# VPAC0_PAR_VPAC_VISS0_S_VBUSP_VISS_RAWFE_CFG_MMR_S_VBUSP_RAWFE_CFG register map
Vendor: Texas Instruments
Peripheral module from a debugger description file (folder J7ES).
Registers are 32-bit, access per field, reset values left out (the file's numbers can be read two ways) unless marked. A register's access mark holds for its fields unless they carry their own. Offsets are as the file gives them; lines under a group give offsets from that group; [hi:lo] are bit positions; {n}, {i} and the like mark numbered series; 'fields as' and 'values as' point back to an identical list; <NAME> marks a mode.

## VPAC0_PAR_VPAC_VISS0_S_VBUSP_VISS_RAWFE_CFG_MMR_S_VBUSP_RAWFE_CFG
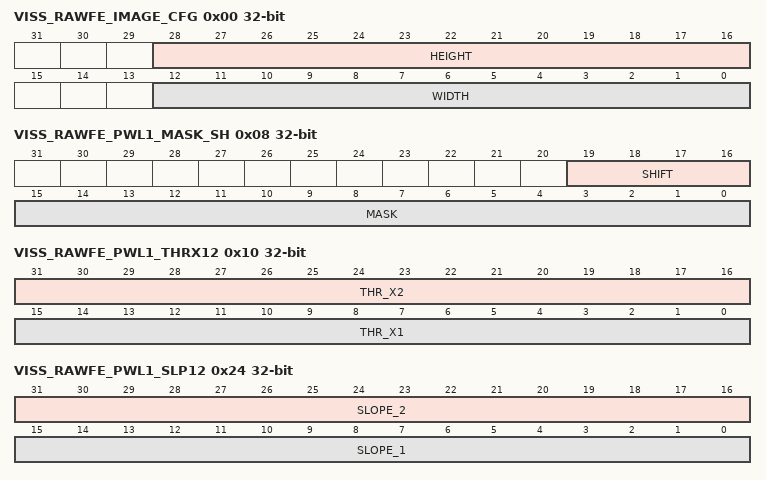
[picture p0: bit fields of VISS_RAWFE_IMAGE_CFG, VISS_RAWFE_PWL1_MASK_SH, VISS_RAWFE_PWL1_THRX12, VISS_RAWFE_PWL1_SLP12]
0x00 VISS_RAWFE_IMAGE_CFG — Input image width and height.
  [28:16] HEIGHT rw — image height
  [12:0] WIDTH rw — image width
0x04 VISS_RAWFE_SHADOW_CFG rw — shadow configuration
  [0] LUT3_SHDW_EN — use LUT2 ram as LUT table for LUT3 processing
0x08 VISS_RAWFE_PWL1_MASK_SH — Long frame PWL mask and shift values
  [19:16] SHIFT rw — number of right shift
  [15:0] MASK rw — mask bit pattern
0x0C VISS_RAWFE_PWL1_EN — Long frame PWL enable
  [0] ENABLE rw
0x10 VISS_RAWFE_PWL1_THRX12 rw — Long frame PWL threshold X1 and X2 - Unsigned
  [31:16] THR_X2 — threshold X2
  [15:0] THR_X1 — threshold X1
0x14 VISS_RAWFE_PWL1_THRX3 — Long frame PWL threshold X3 - Unsigned
  [15:0] THR_X3 rw — threshold X3
{0x14+4i} VISS_RAWFE_PWL1_THRY{i} (i=1..3) — Long frame PWL threshold Y{i} - Unsigned
  [23:0] THR_Y{i} rw — threshold Y{i}
0x24 VISS_RAWFE_PWL1_SLP12 rw — Long frame PWL slope 1 and 2 - Unsigned
  [31:16] SLOPE_2, [15:0] SLOPE_1
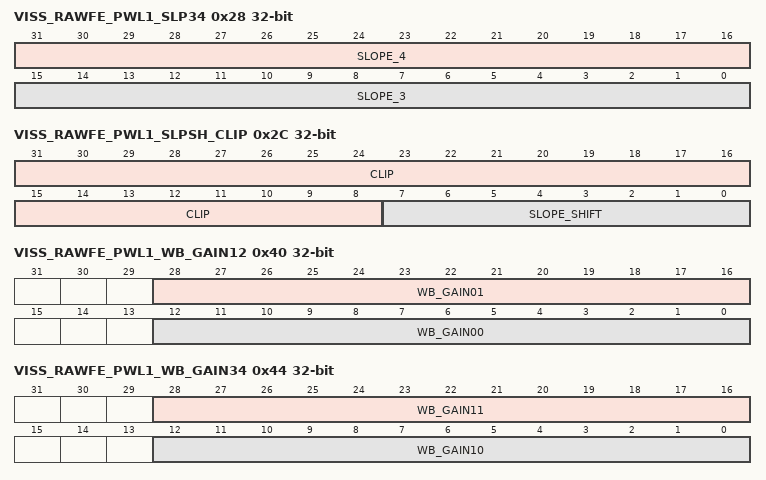
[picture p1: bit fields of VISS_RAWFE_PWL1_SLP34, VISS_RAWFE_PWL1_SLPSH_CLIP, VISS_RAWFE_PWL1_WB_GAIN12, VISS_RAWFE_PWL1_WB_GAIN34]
0x28 VISS_RAWFE_PWL1_SLP34 rw — Long frame PWL slope 3 and 4 - Unsigned
  [31:16] SLOPE_4, [15:0] SLOPE_3
0x2C VISS_RAWFE_PWL1_SLPSH_CLIP rw — Long frame PWL slope shift and clip
  [31:8] CLIP — clip value
  [7:0] SLOPE_SHIFT — shift value for slope, must not exceed decimal 33.
0x30 VISS_RAWFE_PWL1_OFF1 — Long frame Offset 1
  [23:0] OFST00 rw — S24, Offset at pixel 00
0x34 VISS_RAWFE_PWL1_OFF2 — Long frame Offset 2
  [23:0] OFST01 rw — S24, Offset at pixel 01
0x38 VISS_RAWFE_PWL1_OFF3 — Long frame Offset 3
  [23:0] OFST10 rw — S24, Offset at pixel 10
0x3C VISS_RAWFE_PWL1_OFF4 — Long frame Offset 4
  [23:0] OFST11 rw — S24, Offset at pixel 11
0x40 VISS_RAWFE_PWL1_WB_GAIN12 — Long Frame white balance gain 1 and 2
  [28:16] WB_GAIN01 rw — U13Q9, WB gain at pixel 01
  [12:0] WB_GAIN00 rw — U13Q9, WB gain at pixel 00
0x44 VISS_RAWFE_PWL1_WB_GAIN34 — Long Frame white balance gain 3 and 4
  [28:16] WB_GAIN11 rw — U13Q9, WB gain at pixel 11
  [12:0] WB_GAIN10 rw — U13Q9, WB gain at pixel 10
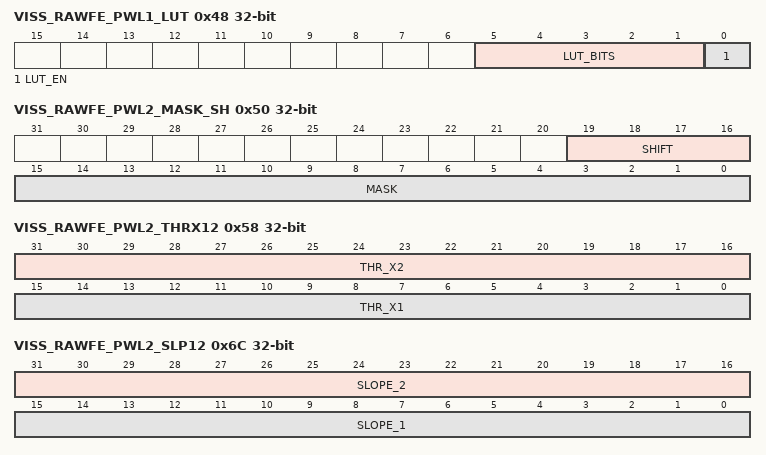
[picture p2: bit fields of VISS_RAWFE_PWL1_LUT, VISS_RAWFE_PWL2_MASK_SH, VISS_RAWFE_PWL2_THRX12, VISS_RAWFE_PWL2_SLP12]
0x48 VISS_RAWFE_PWL1_LUT — Long frame PWL LUT configuration
  [5:1] LUT_BITS rw — LUT input bit depth, up to 24
  [0] LUT_EN rw — enable LUT based compression
0x4C VISS_RAWFE_PWL1_LUTCLIP — Long frame PWL LUT output clip value
  [15:0] LUTCLIP rw — LUT clip value
0x50 VISS_RAWFE_PWL2_MASK_SH — Short frame PWL mask and shift values
  fields as VISS_RAWFE_PWL1_MASK_SH
0x54 VISS_RAWFE_PWL2_EN — Short frame PWL enable
  [0] ENABLE rw
0x58 VISS_RAWFE_PWL2_THRX12 rw — Short frame PWL threshold X1 and X2 - Unsigned
  [31:16] THR_X2 — threshold X2
  [15:0] THR_X1 — threshold X1
0x5C VISS_RAWFE_PWL2_THRX3 — Short frame PWL threshold X3 - Unsigned
  [15:0] THR_X3 rw — threshold X3
{0x5C+4i} VISS_RAWFE_PWL2_THRY{i} (i=1..3) — Short frame PWL threshold Y{i} - Unsigned
  [23:0] THR_Y{i} rw — threshold Y{i}
0x6C VISS_RAWFE_PWL2_SLP12 rw — Short frame PWL slope 1 and 2 - Unsigned
  [31:16] SLOPE_2, [15:0] SLOPE_1
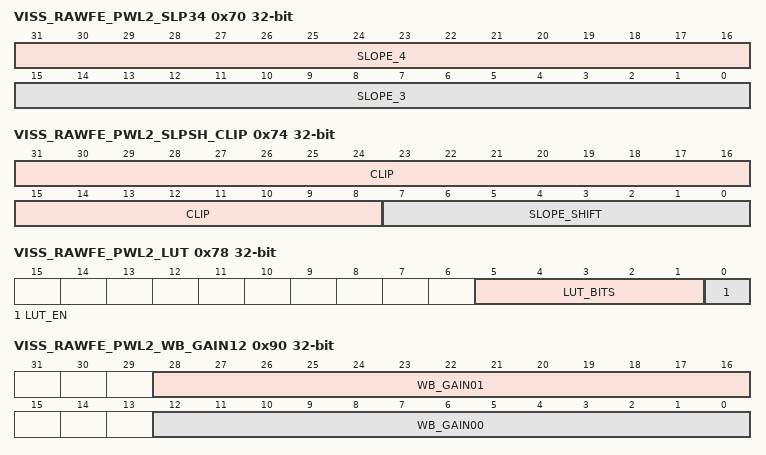
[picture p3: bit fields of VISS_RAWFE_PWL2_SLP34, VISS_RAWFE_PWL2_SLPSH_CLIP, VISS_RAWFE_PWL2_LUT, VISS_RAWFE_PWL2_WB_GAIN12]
0x70 VISS_RAWFE_PWL2_SLP34 rw — Short frame PWL slope 3 and 4 - Unsigned
  [31:16] SLOPE_4, [15:0] SLOPE_3
0x74 VISS_RAWFE_PWL2_SLPSH_CLIP rw — Short frame PWL slope shift and clip
  [31:8] CLIP — clip value
  [7:0] SLOPE_SHIFT — shift value for slope, must not exceed decimal 33
0x78 VISS_RAWFE_PWL2_LUT — Short frame PWL LUT configuration
  fields as VISS_RAWFE_PWL1_LUT
0x7C VISS_RAWFE_PWL2_LUTCLIP — Short frame PWL LUT output clip value
  [15:0] LUTCLIP rw — LUT clip value
0x80 VISS_RAWFE_PWL2_OFF1 — Short frame WB Offset 1
  [23:0] OFST00 rw — S24, WB Offset at pixel 00
0x84 VISS_RAWFE_PWL2_OFF2 — Short frame Offset 2
  [23:0] OFST01 rw — S24, Offset at pixel 01
0x88 VISS_RAWFE_PWL2_OFF3 — Short frame Offset 3
  [23:0] OFST10 rw — S24, Offset at pixel 10
0x8C VISS_RAWFE_PWL2_OFF4 — Short frame Offset 4
  [23:0] OFST11 rw — S24, Offset at pixel 11
0x90 VISS_RAWFE_PWL2_WB_GAIN12 — Short Frame white balance gain 1 and 2
  fields as VISS_RAWFE_PWL1_WB_GAIN12
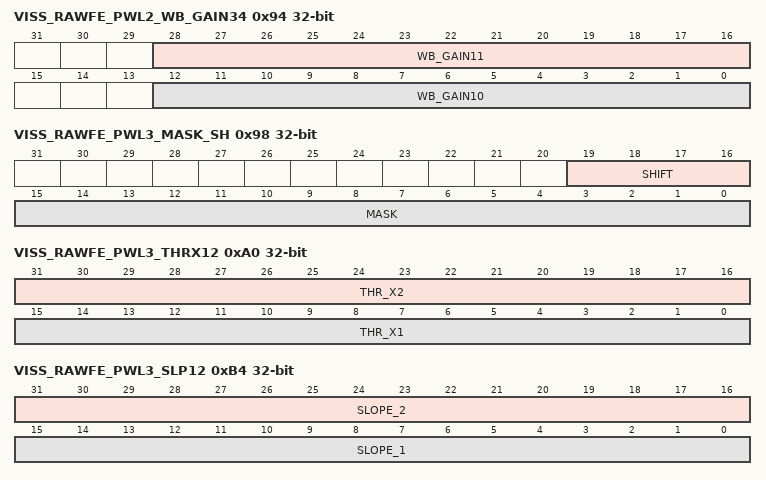
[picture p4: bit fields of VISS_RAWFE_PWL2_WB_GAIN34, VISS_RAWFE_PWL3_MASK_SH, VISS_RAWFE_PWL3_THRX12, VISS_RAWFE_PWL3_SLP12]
0x94 VISS_RAWFE_PWL2_WB_GAIN34 — Short Frame white balance gain 3 and 4
  fields as VISS_RAWFE_PWL1_WB_GAIN34
0x98 VISS_RAWFE_PWL3_MASK_SH — Very short frame PWL mask and shift values
  fields as VISS_RAWFE_PWL1_MASK_SH
0x9C VISS_RAWFE_PWL3_EN — Very short frame PWL enable
  [0] ENABLE rw
0xA0 VISS_RAWFE_PWL3_THRX12 rw — Very short frame PWL threshold X1 and X2 - Unsigned
  [31:16] THR_X2 — threshold X2
  [15:0] THR_X1 — threshold X1
0xA4 VISS_RAWFE_PWL3_THRX3 — Very short frame PWL threshold X3 - Unsigned
  [15:0] THR_X3 rw — threshold X3
{0xA4+4i} VISS_RAWFE_PWL3_THRY{i} (i=1..3) — Very short frame PWL threshold Y{i} - Unsigned
  [23:0] THR_Y{i} rw — threshold Y{i}
0xB4 VISS_RAWFE_PWL3_SLP12 rw — Very short frame PWL slope 1 and 2 - Unsigned
  [31:16] SLOPE_2, [15:0] SLOPE_1
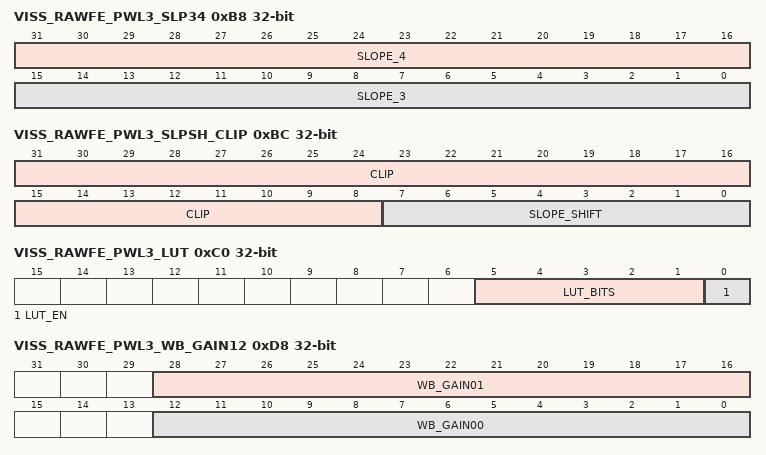
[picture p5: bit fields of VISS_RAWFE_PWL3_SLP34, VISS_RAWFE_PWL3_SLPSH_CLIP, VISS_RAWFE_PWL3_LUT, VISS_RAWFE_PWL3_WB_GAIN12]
0xB8 VISS_RAWFE_PWL3_SLP34 rw — Very short frame PWL slope 3 and 4 - Unsigned
  [31:16] SLOPE_4, [15:0] SLOPE_3
0xBC VISS_RAWFE_PWL3_SLPSH_CLIP rw — Very short frame PWL slope shift and clip
  fields as VISS_RAWFE_PWL2_SLPSH_CLIP
0xC0 VISS_RAWFE_PWL3_LUT — Very short frame PWL LUT configuration
  fields as VISS_RAWFE_PWL1_LUT
0xC4 VISS_RAWFE_PWL3_LUTCLIP — Very short frame PWL LUT output clip value
  [15:0] LUTCLIP rw — LUT clip value
0xC8 VISS_RAWFE_PWL3_OFF1 — Very Short frame Offset 1
  [23:0] OFST00 rw — S24, Offset at pixel 00
0xCC VISS_RAWFE_PWL3_OFF2 — Very Short frame Offset 2
  [23:0] OFST01 rw — S24, Offset at pixel 01
0xD0 VISS_RAWFE_PWL3_OFF3 — Very Short frame Offset 3
  [23:0] OFST10 rw — S24, Offset at pixel 10
0xD4 VISS_RAWFE_PWL3_OFF4 — Very Short frame Offset 4
  [23:0] OFST11 rw — S24, Offset at pixel 11
0xD8 VISS_RAWFE_PWL3_WB_GAIN12 — Very Short Frame white balance gain 1 and 2
  fields as VISS_RAWFE_PWL1_WB_GAIN12
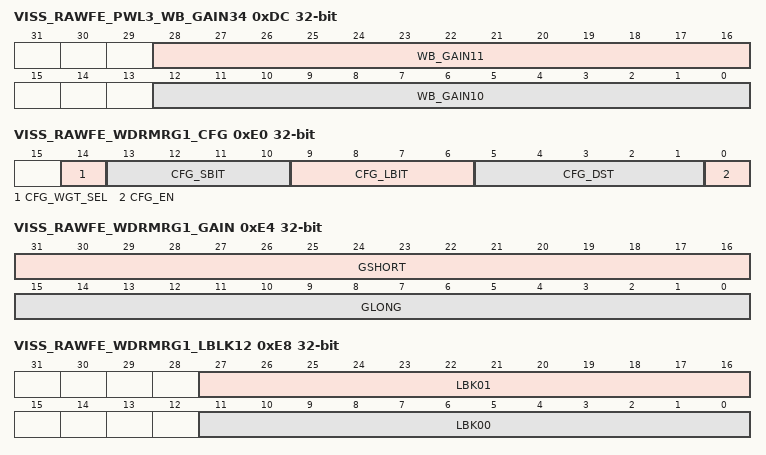
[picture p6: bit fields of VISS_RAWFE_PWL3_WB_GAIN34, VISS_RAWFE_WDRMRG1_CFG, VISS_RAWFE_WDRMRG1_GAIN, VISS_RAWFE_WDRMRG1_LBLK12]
0xDC VISS_RAWFE_PWL3_WB_GAIN34 — Very Short Frame white balance gain 3 and 4
  fields as VISS_RAWFE_PWL1_WB_GAIN34
0xE0 VISS_RAWFE_WDRMRG1_CFG — First stage WDR merge configuration
  [14] CFG_WGT_SEL rw — Select source for weight calculation (
  [13:10] CFG_SBIT rw — U4, short exposure image bit shift
  [9:6] CFG_LBIT rw — U4, long exposure image bit shift
  [5:1] CFG_DST rw — U5, down shift value after WDR merge
  [0] CFG_EN rw — enable
0xE4 VISS_RAWFE_WDRMRG1_GAIN rw — First stage WDR merge gain
  [31:16] GSHORT — U16Q15, gain for long frame
  [15:0] GLONG — U16Q15, gain for short frame
0xE8 VISS_RAWFE_WDRMRG1_LBLK12 — First stage WDR merge black level 1 and 2 for long frame
  [27:16] LBK01 rw — U12, black level for long frame at pixel 01
  [11:0] LBK00 rw — U12, black level for long frame at pixel 00
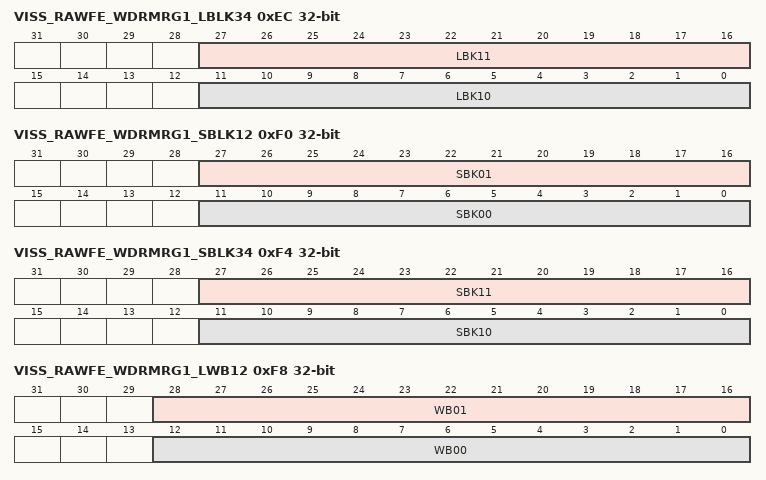
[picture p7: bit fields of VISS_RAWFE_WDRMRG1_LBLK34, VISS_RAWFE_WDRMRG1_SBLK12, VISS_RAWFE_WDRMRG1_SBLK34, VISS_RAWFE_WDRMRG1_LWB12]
0xEC VISS_RAWFE_WDRMRG1_LBLK34 — First stage WDR merge black level 3 and 4 for long frame
  [27:16] LBK11 rw — U12, black level for long frame at pixel 11
  [11:0] LBK10 rw — U12, black level for long frame at pixel 10
0xF0 VISS_RAWFE_WDRMRG1_SBLK12 — First stage WDR merge black level 1 and 2 for short frame
  [27:16] SBK01 rw — U12, black level for short frame at pixel 01
  [11:0] SBK00 rw — U12, black level for short frame at pixel 00
0xF4 VISS_RAWFE_WDRMRG1_SBLK34 — First stage WDR merge black level 3 and 4 for short frame
  [27:16] SBK11 rw — U12, black level for short frame at pixel 11
  [11:0] SBK10 rw — U12, black level for short frame at pixel 10
0xF8 VISS_RAWFE_WDRMRG1_LWB12 — First stage WDR merge WB gain 1 and 2 for long frame
  [28:16] WB01 rw — U13Q9, WB gain for long frame at pixel 01
  [12:0] WB00 rw — U13Q9, WB gain for long frame at pixel 00
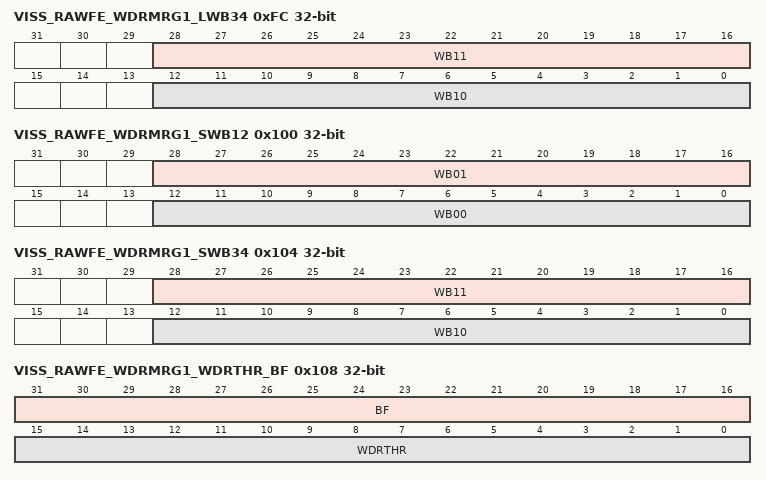
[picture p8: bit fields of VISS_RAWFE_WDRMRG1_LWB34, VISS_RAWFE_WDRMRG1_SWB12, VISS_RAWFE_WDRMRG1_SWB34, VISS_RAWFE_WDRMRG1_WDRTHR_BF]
0xFC VISS_RAWFE_WDRMRG1_LWB34 — First stage WDR merge WB gain 3 and 4 for long frame
  [28:16] WB11 rw — U13Q9, WB gain for long frame at pixel 11
  [12:0] WB10 rw — U13Q9, WB gain for long frame at pixel 10
0x100 VISS_RAWFE_WDRMRG1_SWB12 — First stage WDR merge WB gain 1 and 2 for short frame
  [28:16] WB01 rw — U13Q9, WB gain for short frame at pixel 01
  [12:0] WB00 rw — U13Q9, WB gain for short frame at pixel 00
0x104 VISS_RAWFE_WDRMRG1_SWB34 — First stage WDR merge WB gain 3 and 4 for short frame
  [28:16] WB11 rw — U13Q9, WB gain for short frame at pixel 11
  [12:0] WB10 rw — U13Q9, WB gain for short frame at pixel 10
0x108 VISS_RAWFE_WDRMRG1_WDRTHR_BF rw — First stage WDR merge parameter WDRTHR and BF
  [31:16] BF — S16, bf parameter for merge
  [15:0] WDRTHR — U16, WDR threshold for merge
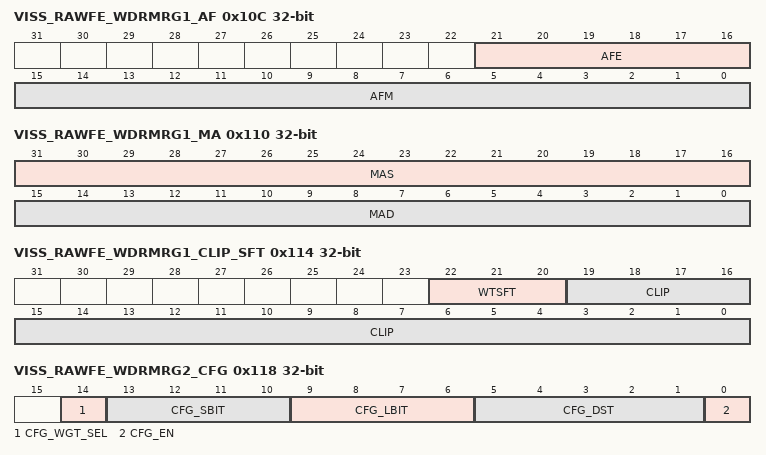
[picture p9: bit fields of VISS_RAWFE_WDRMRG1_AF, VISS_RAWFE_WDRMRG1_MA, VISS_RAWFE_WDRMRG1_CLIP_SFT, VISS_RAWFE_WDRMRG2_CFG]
0x10C VISS_RAWFE_WDRMRG1_AF — First stage WDR merge parameter AF
  [21:16] AFE rw — U6, af_e parameter for merge
  [15:0] AFM rw — S16, af_m parameter for merge
0x110 VISS_RAWFE_WDRMRG1_MA rw — First stage WDR merge parameter MA
  [31:16] MAS — U16, slope for merge MA filter
  [15:0] MAD — U16, lower threshold for merge MA filter
0x114 VISS_RAWFE_WDRMRG1_CLIP_SFT — First stage WDR merge clip value and shift before weight block
  [22:20] WTSFT rw — U3, shift before weight block
  [19:0] CLIP rw — U20, output clip value.
0x118 VISS_RAWFE_WDRMRG2_CFG — Second stage WDR merge configuration
  fields as VISS_RAWFE_WDRMRG1_CFG
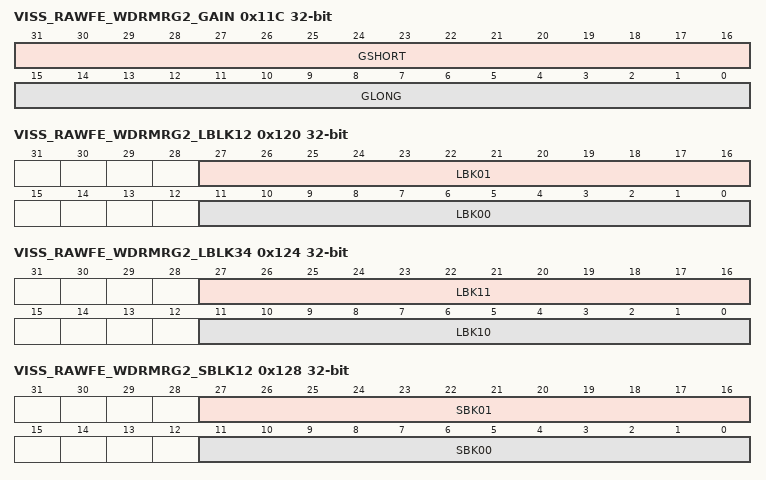
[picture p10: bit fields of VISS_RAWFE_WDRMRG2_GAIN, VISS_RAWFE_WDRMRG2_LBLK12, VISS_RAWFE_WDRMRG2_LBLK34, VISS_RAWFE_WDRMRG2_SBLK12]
0x11C VISS_RAWFE_WDRMRG2_GAIN rw — Second stage WDR merge gain
  fields as VISS_RAWFE_WDRMRG1_GAIN
0x120 VISS_RAWFE_WDRMRG2_LBLK12 — Second stage WDR merge black level 1 and 2 for long frame
  fields as VISS_RAWFE_WDRMRG1_LBLK12
0x124 VISS_RAWFE_WDRMRG2_LBLK34 — Second stage WDR merge black level 3 and 4 for long frame
  fields as VISS_RAWFE_WDRMRG1_LBLK34
0x128 VISS_RAWFE_WDRMRG2_SBLK12 — Second stage WDR merge black level 1 and 2 for short frame
  fields as VISS_RAWFE_WDRMRG1_SBLK12
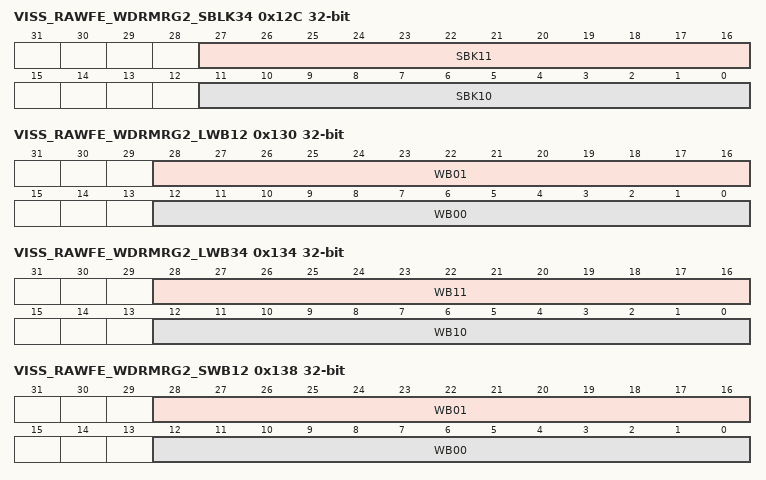
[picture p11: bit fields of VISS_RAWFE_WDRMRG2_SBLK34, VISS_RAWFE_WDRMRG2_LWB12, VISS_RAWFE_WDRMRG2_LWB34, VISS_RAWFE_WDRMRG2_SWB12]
0x12C VISS_RAWFE_WDRMRG2_SBLK34 — Second stage WDR merge black level 3 and 4 for short frame
  fields as VISS_RAWFE_WDRMRG1_SBLK34
0x130 VISS_RAWFE_WDRMRG2_LWB12 — Second stage WDR merge WB gain 1 and 2 for long frame
  fields as VISS_RAWFE_WDRMRG1_LWB12
0x134 VISS_RAWFE_WDRMRG2_LWB34 — Second stage WDR merge WB gain 3 and 4 for long frame
  fields as VISS_RAWFE_WDRMRG1_LWB34
0x138 VISS_RAWFE_WDRMRG2_SWB12 — Second stage WDR merge WB gain 1 and 2 for short frame
  fields as VISS_RAWFE_WDRMRG1_SWB12
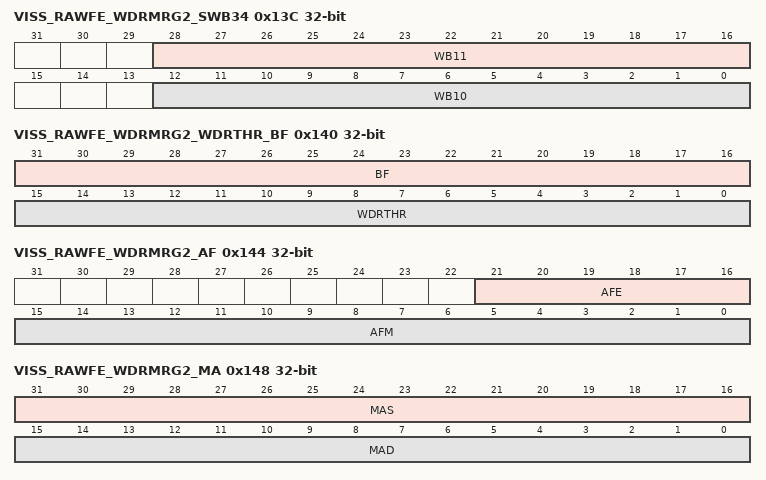
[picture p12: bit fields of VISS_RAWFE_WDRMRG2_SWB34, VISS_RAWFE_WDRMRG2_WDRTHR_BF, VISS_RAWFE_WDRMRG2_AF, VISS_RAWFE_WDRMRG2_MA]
0x13C VISS_RAWFE_WDRMRG2_SWB34 — Second stage WDR merge WB gain 3 and 4 for short frame
  fields as VISS_RAWFE_WDRMRG1_SWB34
0x140 VISS_RAWFE_WDRMRG2_WDRTHR_BF rw — Second stage WDR merge parameter WDRTHR and BF
  fields as VISS_RAWFE_WDRMRG1_WDRTHR_BF
0x144 VISS_RAWFE_WDRMRG2_AF — Second stage WDR merge parameter AF
  fields as VISS_RAWFE_WDRMRG1_AF
0x148 VISS_RAWFE_WDRMRG2_MA rw — Second stage WDR merge parameter MA
  fields as VISS_RAWFE_WDRMRG1_MA
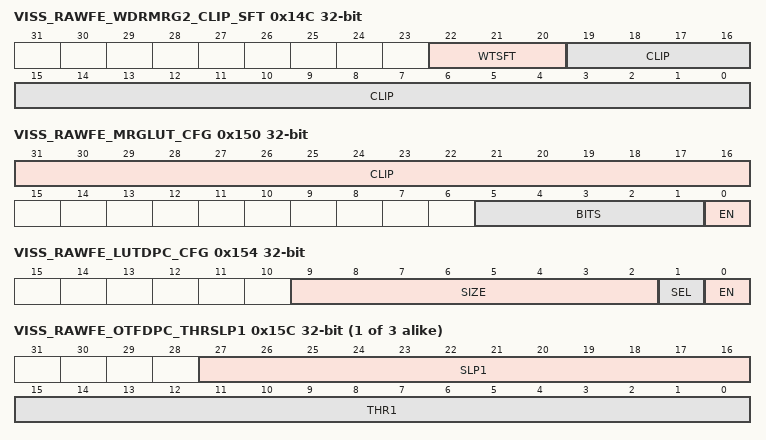
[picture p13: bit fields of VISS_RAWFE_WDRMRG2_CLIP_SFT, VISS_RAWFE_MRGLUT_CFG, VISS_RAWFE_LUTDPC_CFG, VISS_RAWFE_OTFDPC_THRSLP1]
0x14C VISS_RAWFE_WDRMRG2_CLIP_SFT — Second stage WDR merge clip value and shift before weight block
  [22:20] WTSFT rw — U3, shift before weight block
  [19:0] CLIP rw — U20, output clip value
0x150 VISS_RAWFE_MRGLUT_CFG — Merge LUT configuration
  [31:16] CLIP rw — U16, LUT output clip
  [5:1] BITS rw — U5, LUT input bit depth, up to 24
  [0] EN rw — LUT enable
0x154 VISS_RAWFE_LUTDPC_CFG — LUTDPC configuration
  [9:2] SIZE rw — U8, number of LUT entires - 1
  [1] SEL rw — replace with black (0) or whithe (1)
  [0] EN rw — LUTDPC enable
0x158 VISS_RAWFE_OTFDPC_EN — OTFDPC enable
  [0] EN rw — OTF DPC enable
{0x158+4i} VISS_RAWFE_OTFDPC_THRSLP{i} (i=1..3) — OTFDPC threshold and slope {i}
  [27:16] SLP1 rw — S12Q8, slope at {512i-512}
  [15:0] THR1 rw — U16, threshold at {512i-512}
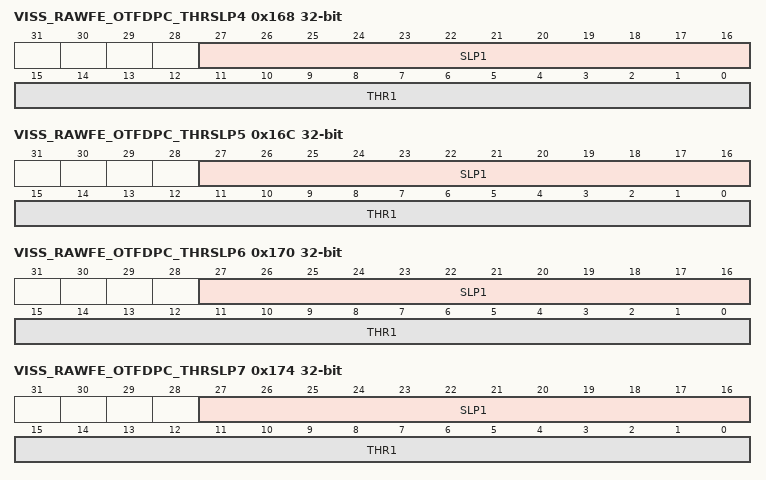
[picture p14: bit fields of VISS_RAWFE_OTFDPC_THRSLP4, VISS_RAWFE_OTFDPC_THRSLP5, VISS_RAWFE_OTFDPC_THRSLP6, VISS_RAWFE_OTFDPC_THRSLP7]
0x168 VISS_RAWFE_OTFDPC_THRSLP4 — OTFDPC threshold and slope 4
  [27:16] SLP1 rw — S12Q8, slope at 2048
  [15:0] THR1 rw — U16, threshold at 2048
0x16C VISS_RAWFE_OTFDPC_THRSLP5 — OTFDPC threshold and slope 5
  [27:16] SLP1 rw — S12Q8, slope at 4096
  [15:0] THR1 rw — U16, threshold at 4096
0x170 VISS_RAWFE_OTFDPC_THRSLP6 — OTFDPC threshold and slope 6
  [27:16] SLP1 rw — S12Q8, slope at 8192
  [15:0] THR1 rw — U16, threshold at 8192
0x174 VISS_RAWFE_OTFDPC_THRSLP7 — OTFDPC threshold and slope 7
  [27:16] SLP1 rw — S12Q8, slope at 16384
  [15:0] THR1 rw — U16, threshold at 16384
0x178 VISS_RAWFE_OTFDPC_THRSLP8 — OTFDPC threshold and slope 8
  [27:16] SLP1 rw — S12Q8, slope at 32768
  [15:0] THR1 rw — U16, threshold at 32768
0x17C VISS_RAWFE_LSC_CFG — LSC configuration
  [9:7] GAIN_FORMAT rw — LSC LUT gain format,
  [6:4] MODE_N rw — vertical LSC LUT downsampling,
  [3:1] MODE_M rw — horizontal LSC LUT downsampling,
  [0] EN rw — LSC enable
0x180 VISS_RAWFE_WB2_OFFSET12 rw — WB2 white balance offset 1 and 2
  [31:16] WB_OFST01 — S16, WB offset at pixel 01
  [15:0] WB_OFST00 — S16, WB offset at pixel 00
0x184 VISS_RAWFE_WB2_OFFSET34 rw — WB2 white balance offset 3 and 4
  [31:16] WB_OFST11 — S16, WB offset at pixel 11
  [15:0] WB_OFST10 — S16, WB offset at pixel 10
0x188 VISS_RAWFE_WB2_GAIN12 — WB2 white balance gain 1 and 2
  fields as VISS_RAWFE_PWL1_WB_GAIN12
0x18C VISS_RAWFE_WB2_GAIN34 — WB2 white balance gain 3 and 4
  fields as VISS_RAWFE_PWL1_WB_GAIN34
0x190 VISS_RAWFE_H3AMUX_CFG — H3A MUX configuration
  [5:2] SHIFT rw — U8, number of right shift, from 0 to 14
  [1:0] SEL rw — H3A input selection,
0x194 VISS_RAWFE_H3ALUT_CFG — H3A LUT configuration
  [25:16] CLIP rw — U10, LUT output clip value
  [5:1] BITS rw — U5, LUT input bit depth, up to 24
  [0] EN rw — LUT enable
0x198 VISS_RAWFE_INT_STAT access not given — status/clear register for rawfe interrupts
  [9] LSC_CFG_ERR — status/clear for lsc config error. (access RW1C)
  [8] DPC_LINE_CFG_ERR — status/clear for dpc line config error. (access RW1C)
  [7] DPC_LUT_CFG_ERR — status/clear for dpc lut configuration error. (access RW1C)
  [6] H3A_ACCM_CFG_ERR — status/clear for h3a accum configuration error. (access RW1C)
  [5] H3A_LINE_CFG_ERR — status/clear for h3a line configuration error. (access RW1C)
  [4] H3A_LUT_CFG_ERR — status/clear for h3a lut configuration error. (access RW1C)
  [3] WDR_LUT_CFG_ERR — status/clear for wdr lut configuration error. (access RW1C)
  [2] LUT3_CFG_ERR — status/clear for lut3 configuration error. (access RW1C)
  [1] LUT2_CFG_ERR — status/clear for lut2 configuration error. (access RW1C)
  [0] LUT1_CFG_ERR — status/clear for lut1 configuration error. (access RW1C)
0x200 VISS_RAWFE_DBG_CTL rw — debug event and control register
  [13:12] DPC_LINE_SEL — select for which dpc line ram to read on debug interface
  [11] PIPE_ADV_EN_EVENT — enable for pixal pipe line advanced
  [10] DPC_OTF_CORR_EN_EVENT — enable for dpc otf corrected a pixel
  [9] LSE_INTF_STALL_EN_EVENT — enable for lse slave port stalled by rawfe
  [8] LSE_MST_STALL_EN_EVENT — enable for lse maaster port stalled on H3A out I/F
  [7] LSE_SLV_STALL_EN_EVENT — enable for lse not sending data in frame on pixel I/F
  [6] HE_EN_EVENT — enable for horizantal end
  [5] HS_EN_EVENT — enable for horizantal start
  [4] VE_EN_EVENT — enable for verticle end
  [3] VS_EN_EVENT — enable for verticle start
  [2] X_Y_EN_EVENT — enable for x,y position match event
  [1] X_Y_EN_HALT — enable for x,y position match halt
  [0] DBG_EN — Enable debug features, set to '0' to disable all events
0x204 VISS_RAWFE_DBG_HWBP rw — x,y event for event matching
  [28:16] Y_POS — pixel y position
  [12:0] X_POS — pixel x position
0x208 VISS_RAWFE_DBG_STAT1 access not given — status/clear register for debug events
  [11] PIPE_ADV_EVENT — status/clear for pixal pipe line advanced (access RW1C)
  [10] DPC_OTF_CORR_EVENT — status/clear for dpc otf corrected a pixel. (access RW1C)
  [9] LSE_INTF_STALL_EVENT — status/clear for lse slave port stalled by rawfe. (access RW1C)
  [8] LSE_MST_STALL_EVENT — status/clear for lse maaster port stalled. (access RW1C)
  [7] LSE_SLV_STALL_EVENT — status/clear for lse not sending data in frame. (access RW1C)
  [6] HE_EVENT — status/clear for horizantal end. (access RW1C)
  [5] HS_EVENT — status/clear for horizantal start. (access RW1C)
  [4] VE_EVENT — status/clear for verticle end. (access RW1C)
  [3] VS_EVENT — status/clear for verticle start. (access RW1C)
  [2] X_Y_EVENT — status/clear for x,y position match event. (access RW1C)
  [1] X_Y_HALT — status/clear for x,y position match halt. (access RW1C)
0x20C VISS_RAWFE_DBG_STAT2 ro — current x,y position in frame
  [28:16] Y_POS — current y position
  [12:0] X_POS — current x position
0x210 VISS_RAWFE_DBG_STAT3 ro — internal state status
  [31:2] DPC_MIRROR_STAT — dpc mirror status
  [1:0] DPC_LINE_RAM_CTL — ram control for understanding the phase of DPC line rams circular buffer for debug reads
0x214 VISS_RAWFE_DBG_STAT4 ro — internal state status
  [31:0] LSC_DBG_STAT — lsc state machine
